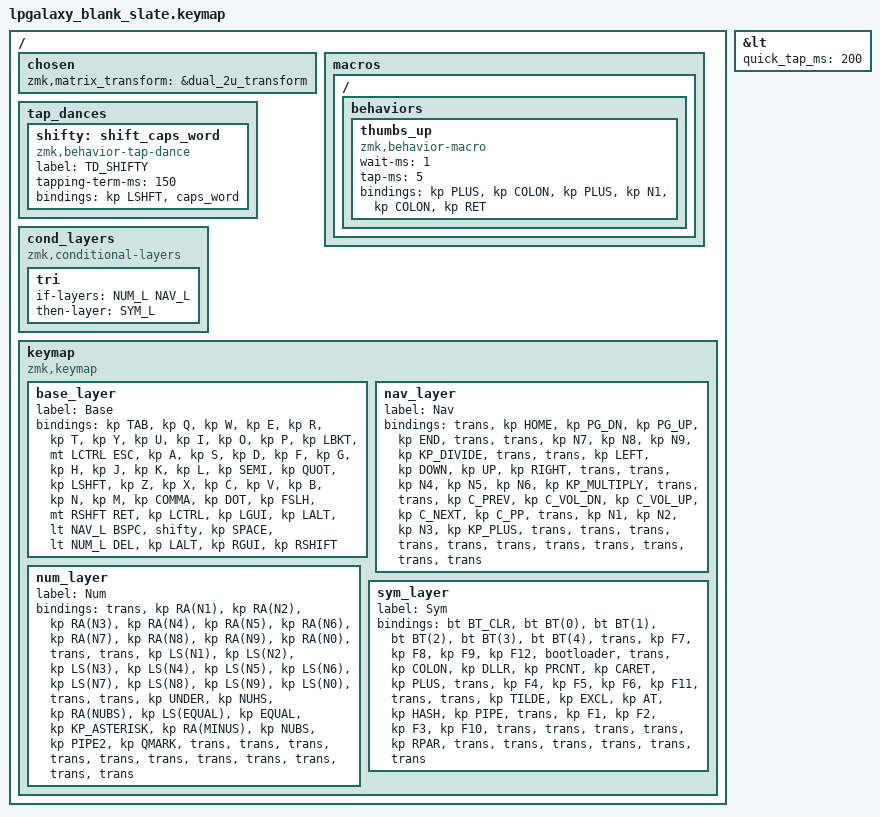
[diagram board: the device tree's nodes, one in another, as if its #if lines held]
/*
 * Copyright (c) 2022 Pete Johanson
 *
 * SPDX-License-Identifier: MIT
 */

#include <behaviors.dtsi>
#include <dt-bindings/zmk/keys.h>
#include <dt-bindings/zmk/bt.h>
#include <dt-bindings/zmk/outputs.h>

#define QWERTY_BASE 1

#define TBLE_ORTHO   1
// #define TBLE_MIT     1
// #define TBLE_DUAL_2U 1

#define NAV_L 1
#define NUM_L 2
#define SYM_L 3

// Using layer taps on thumbs, having quick tap as well helps w/ repeating space/backspace
&lt { quick_tap_ms = <200>; };

#define BT(n) BT_SEL n

/ {
    chosen {
       zmk,matrix_transform =
#ifdef TBLE_DUAL_2U
                       &dual_2u_transform;
#elif defined(TBLE_MIT)
                       &mit_transform;
#else
                       &ortho_transform;
#endif
    };

    macros {
      ZMK_MACRO(thumbs_up,
		wait-ms = <1>;
		tap-ms = <5>;
                bindings = <&kp PLUS &kp COLON &kp PLUS &kp N1 &kp COLON &kp RET>;
		)
    };
    
    tap_dances {
    	shifty: shift_caps_word {
		compatible = "zmk,behavior-tap-dance";
		label = "TD_SHIFTY";
		#binding-cells = <0>;
		tapping-term-ms = <150>;
		bindings = <&kp LSHFT>, <&caps_word>;
	};
    };

// Conditional layer 
    cond_layers {
        compatible = "zmk,conditional-layers";
	tri {
	    if-layers = <NUM_L NAV_L>;
	    then-layer = <SYM_L>;
        };
    };

    keymap {
        compatible = "zmk,keymap";
/* Qwerty
┌────────┬────────┬────────┬────────┬────────┬────────┬────────┬────────┬────────┬────────┬────────┬────────┐
|  Tab       Q        W        E        R        T        Y        U        I        O        P        Å
├────────┼────────┼────────┼────────┼────────┼────────┼────────┼────────┼────────┼────────┼────────┼────────┤
|  Ctrl      A        S        D        F        G        H        J        K        L        Ö        Ä
├────────┼────────┼────────┼────────┼────────┼────────┼────────┼────────┼────────┼────────┼────────┼────────┤
|  Shift     Z        X        C        V        B        N        M        ,        .        -       Enter
├────────┼────────┼────────┼────────┼────────┼────────┴────────┼────────┼────────┼────────┼────────┼────────┤
   Adjust   < >      Win       Alt    Lower         Space         Raise    Left     Down     Up       Right
└────────┴────────┴────────┴────────┴────────┴─────────────────┴────────┴────────┴────────┴────────┴────────┘
 */
        base_layer {
            label = "Base";
            bindings = <
#ifdef QWERTY_BASE
 &kp TAB    &kp Q      &kp W      &kp E       &kp R          &kp T          &kp Y            &kp U          &kp I       &kp O      &kp P         &kp LBKT
 &mt LCTRL ESC &kp A      &kp S      &kp D       &kp F          &kp G          &kp H            &kp J          &kp K       &kp L      &kp SEMI      &kp QUOT
 &kp LSHFT  &kp Z      &kp X      &kp C       &kp V          &kp B          &kp N            &kp M          &kp COMMA   &kp DOT    &kp FSLH      &mt RSHFT RET
#else
 &kp TAB    &kp Q      &kp W      &kp F       &kp P          &kp B          &kp J            &kp L          &kp U       &kp Y      &kp QUOT      &kp LBKT
 &kp LCTRL  &kp A      &kp R      &kp S       &kp T          &kp G          &kp M            &kp N          &kp E       &kp I      &kp O         &kp QUOT
 &kp LSHFT  &kp Z      &kp X      &kp C       &kp D          &kp V          &kp K            &kp H          &kp COMMA   &kp DOT    &kp SEMI      &kp RET
#endif
#ifdef TBLE_DUAL_2U
 &kp LCTRL  &kp LGUI   &kp LALT   &lt NAV_L BSPC         &shifty                        &kp SPACE                &lt NUM_L DEL   &kp LALT   &kp RGUI      &kp RSHIFT
#elif defined(TBLE_MIT)
 &kp LCTRL  &mo SYM_L   &kp LGUI  &kp LALT    &lt NAV_L BSPC     &kp SPACE                   &lt NUM_L DEL  &kp LEFT    &kp UP     &kp DOWN      &kp RIGHT
#else
 &kp LCTRL  &mo SYM_L   &kp LGUI  &kp LALT    &lt NAV_L BSPC      &kp SPACE      &kp RET          &lt NUM_L DEL &kp LEFT    &kp UP     &kp DOWN      &kp RIGHT
#endif
            >;
        };
/* Lower (Num & Nav)
┌────────┬────────┬────────┬────────┬────────┬────────┬────────┬────────┬────────┬────────┬────────┬────────┐
|            Home    PgDn     PgUp     End                         7        8        9        /        \
├────────┼────────┼────────┼────────┼────────┼────────┼────────┼────────┼────────┼────────┼────────┼────────┤
|            Left    Down     Up       Right                       4        5        6        *        "
├────────┼────────┼────────┼────────┼────────┼────────┼────────┼────────┼────────┼────────┼────────┼────────┤
|  caps      Undo    Cut      Copy     Paste    Redo               1        2        3        +
├────────┼────────┼────────┼────────┼────────┼────────┴────────┼────────┼────────┼────────┼────────┼────────┤
|                                                     0
└────────┴────────┴────────┴────────┴────────┴─────────────────┴────────┴────────┴────────┴────────┴────────┘
 */
        nav_layer {
            label = "Nav";
            bindings = <
&trans     &kp HOME   &kp PG_DN     &kp PG_UP      &kp END         &trans      &trans     &kp N7       &kp N8      &kp N9     &kp KP_DIVIDE    &trans
&trans     &kp LEFT   &kp DOWN      &kp UP         &kp RIGHT       &trans      &trans     &kp N4       &kp N5      &kp N6     &kp KP_MULTIPLY  &trans
&trans     &kp C_PREV &kp C_VOL_DN  &kp C_VOL_UP   &kp C_NEXT      &kp C_PP    &trans     &kp N1       &kp N2      &kp N3     &kp KP_PLUS      &trans
#ifdef TBLE_DUAL_2U
&trans  &trans        &trans     &trans              &trans                    &trans       &trans         &trans &trans &trans
#elif defined(TBLE_MIT)
&trans  &trans        &trans     &trans      &trans                &kp N0           &trans      &trans   &trans &trans &trans
#else
&trans  &trans        &trans     &trans      &trans          &trans       &trans    &trans  &trans         &trans &trans &trans
#endif
            >;
        };
/* Raise (Sym)
┌────────┬────────┬────────┬────────┬────────┬────────┬────────┬────────┬────────┬────────┬────────┬────────┐
|            §        @        £        $        €        ^        {        [        ]        }        \     SWE AltGr numrow (with custom keys in the blanks)
├────────┼────────┼────────┼────────┼────────┼────────┼────────┼────────┼────────┼────────┼────────┼────────┤
|            !        "        #        ¤        %        &        /        (        )        =             SWE shift numrow
├────────┼────────┼────────┼────────┼────────┼────────┼────────┼────────┼────────┼────────┼────────┼────────┤
|            ?        '        ¨        `        ´        *        \        <        >        _              Custom row
├────────┼────────┼────────┼────────┼────────┼────────┴────────┼────────┼────────┼────────┼────────┼────────┤
|
└────────┴────────┴────────┴────────┴────────┴─────────────────┴────────┴────────┴────────┴────────┴────────┘
 */
        num_layer {
            label = "Num";
            bindings = <
&trans     &kp RA(N1) &kp RA(N2) &kp RA(N3) &kp RA(N4) &kp RA(N5) &kp RA(N6) &kp RA(N7) &kp RA(N8) &kp RA(N9) &kp RA(N0) &trans
&trans     &kp LS(N1) &kp LS(N2) &kp LS(N3) &kp LS(N4) &kp LS(N5) &kp LS(N6) &kp LS(N7) &kp LS(N8) &kp LS(N9) &kp LS(N0) &trans
&trans     &kp UNDER &kp NUHS &kp RA(NUBS) &kp LS(EQUAL) &kp EQUAL &kp KP_ASTERISK &kp RA(MINUS) &kp NUBS &kp PIPE2 &kp QMARK &trans
#ifdef TBLE_DUAL_2U
&trans  &trans       &trans     &trans             &trans                 &trans            &trans         &trans &trans &trans
#elif defined(TBLE_MIT)
&trans  &trans       &trans     &trans     &trans           &none            &trans        &trans       &trans &trans &trans
#else
&trans  &trans       &trans     &trans      &trans    &none         &none     &trans        &trans    &trans &trans &trans
#endif
            >;
        };
/* FN (FN,Bluetooth)
┌────────┬────────┬────────┬────────┬────────┬────────┬────────┬────────┬────────┬────────┬────────┬────────┐
|BT Clear   BT0      BT1      BT2      BT3      BT4                F7       F8       F9      F12
├────────┼────────┼────────┼────────┼────────┼────────┼────────┼────────┼────────┼────────┼────────┼────────┤
|                                                                  F4       F5       F6      F11
├────────┼────────┼────────┼────────┼────────┼────────┼────────┼────────┼────────┼────────┼────────┼────────┤
|                                                                  F1       F2       F3      F10
├────────┼────────┼────────┼────────┼────────┼────────┴────────┼────────┼────────┼────────┼────────┼────────┤
|
└────────┴────────┴────────┴────────┴────────┴─────────────────┴────────┴────────┴────────┴────────┴────────┘
 */
        sym_layer {
            label = "Sym";
            bindings = <
&bt BT_CLR &bt BT(0)  &bt BT(1)  &bt BT(2)   &bt BT(3)    &bt BT(4)    &trans     &kp F7    &kp F8       &kp F9       &kp F12     &bootloader
&trans     &kp COLON  &kp DLLR   &kp PRCNT   &kp CARET    &kp PLUS     &trans     &kp F4    &kp F5       &kp F6       &kp F11     &trans
&trans     &kp TILDE  &kp EXCL   &kp AT      &kp HASH     &kp PIPE     &trans     &kp F1    &kp F2       &kp F3       &kp F10     &trans
#ifdef TBLE_DUAL_2U
&trans &trans        &trans     &kp RPAR                &trans                    &trans       &trans         &trans &trans &trans
#elif defined(TBLE_MIT)
&trans &trans        &trans     &kp RPAR        &trans                &trans             &trans      &trans   &trans &trans &trans
#else
&trans &trans        &trans     &kp RPAR        &trans          &trans       &trans    &trans  &trans         &trans &trans &trans
#endif
            >;
        };


    };
};

